AUTOSAR XML (schema 00045)
package /Cps
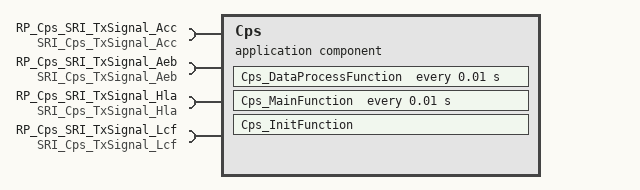
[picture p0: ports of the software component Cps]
  application sw component type Cps  # Communication Process of Sender
    4 x require port:
      RP_Cps_SRI_TxSignal_Acc: required-interface=SRI_Cps_TxSignal_Acc
      RP_Cps_SRI_TxSignal_Aeb: required-interface=SRI_Cps_TxSignal_Aeb
      RP_Cps_SRI_TxSignal_Hla: required-interface=SRI_Cps_TxSignal_Hla
      RP_Cps_SRI_TxSignal_Lcf: required-interface=SRI_Cps_TxSignal_Lcf
    behavior Cps_IB: handle-termination-and-restart=NO-SUPPORT
      init event InitEvent_Cps_InitFunction: start-on-event=Cps_InitFunction
      timing event TimingEvent_Cps_DataProcessFunction: start-on-event=Cps_DataProcessFunction, period=0.01
      timing event TimingEvent_Cps_MainFunction: start-on-event=Cps_MainFunction, period=0.01
      runnable Cps_DataProcessFunction
      runnable Cps_InitFunction
      runnable Cps_MainFunction
        data-receive-point-by-arguments:
          57 x access:
            drparg_Cps_SignalPhyData_ACC: accessed-variable=RP_Cps_SRI_TxSignal_Lcf.Cps_SignalPhyData_ACC_HostLaneLeftStatus
            drparg_Cps_SignalPhyData_ACC0: accessed-variable=RP_Cps_SRI_TxSignal_Lcf.Cps_SignalPhyData_ACC_HostLaneRightStatus
            drparg_Cps_SignalPhyData_ACC1: accessed-variable=RP_Cps_SRI_TxSignal_Lcf.Cps_SignalPhyData_ACC_LatAngReq
            drparg_Cps_SignalPhyData_ACC2: accessed-variable=RP_Cps_SRI_TxSignal_Lcf.Cps_SignalPhyData_ACC_LatAngReqActive
            drparg_Cps_SignalPhyData_FC_: accessed-variable=RP_Cps_SRI_TxSignal_Lcf.Cps_SignalPhyData_FC_HostLaneLeftStatus
            drparg_Cps_SignalPhyData_FC_0: accessed-variable=RP_Cps_SRI_TxSignal_Acc.Cps_SignalPhyData_FC_ACC_temp
            drparg_Cps_SignalPhyData_FC_1: accessed-variable=RP_Cps_SRI_TxSignal_Aeb.Cps_SignalPhyData_FC_AEBActive
            drparg_Cps_SignalPhyData_FC_10: accessed-variable=RP_Cps_SRI_TxSignal_Aeb.Cps_SignalPhyData_FC_AEBTargetmode
            drparg_Cps_SignalPhyData_FC_11: accessed-variable=RP_Cps_SRI_TxSignal_Aeb.Cps_SignalPhyData_FC_AEBTextInfo
            drparg_Cps_SignalPhyData_FC_12: accessed-variable=RP_Cps_SRI_TxSignal_Aeb.Cps_SignalPhyData_FC_AEBVehilceHoldReq
            drparg_Cps_SignalPhyData_FC_13: accessed-variable=RP_Cps_SRI_TxSignal_Aeb.Cps_SignalPhyData_FC_OBJ_AEB_ID
            drparg_Cps_SignalPhyData_FC_14: accessed-variable=RP_Cps_SRI_TxSignal_Aeb.Cps_SignalPhyData_FC_AEBStatus
            drparg_Cps_SignalPhyData_FC_15: accessed-variable=RP_Cps_SRI_TxSignal_Aeb.Cps_SignalPhyData_FC_AEBTargetAy
            drparg_Cps_SignalPhyData_FC_16: accessed-variable=RP_Cps_SRI_TxSignal_Aeb.Cps_SignalPhyData_FC_AEBTargetAx
            drparg_Cps_SignalPhyData_FC_17: accessed-variable=RP_Cps_SRI_TxSignal_Aeb.Cps_SignalPhyData_FC_AEBTargetProb
            drparg_Cps_SignalPhyData_FC_18: accessed-variable=RP_Cps_SRI_TxSignal_Aeb.Cps_SignalPhyData_FC_AEBTargetLatRelSpeed
            drparg_Cps_SignalPhyData_FC_19: accessed-variable=RP_Cps_SRI_TxSignal_Aeb.Cps_SignalPhyData_FC_FCWStatus
            drparg_Cps_SignalPhyData_FC_2: accessed-variable=RP_Cps_SRI_TxSignal_Aeb.Cps_SignalPhyData_FC_AEBCtrlType
            drparg_Cps_SignalPhyData_FC_20: accessed-variable=RP_Cps_SRI_TxSignal_Aeb.Cps_SignalPhyData_FC_PrefillActive
            drparg_Cps_SignalPhyData_FC_21: accessed-variable=RP_Cps_SRI_TxSignal_Aeb.Cps_SignalPhyData_FC_AWBlevel
            drparg_Cps_SignalPhyData_FC_22: accessed-variable=RP_Cps_SRI_TxSignal_Aeb.Cps_SignalPhyData_FC_AWBActive
            drparg_Cps_SignalPhyData_FC_23: accessed-variable=RP_Cps_SRI_TxSignal_Aeb.Cps_SignalPhyData_FC_FCWActive
            drparg_Cps_SignalPhyData_FC_24: accessed-variable=RP_Cps_SRI_TxSignal_Aeb.Cps_SignalPhyData_FC_ABAlevel
            drparg_Cps_SignalPhyData_FC_25: accessed-variable=RP_Cps_SRI_TxSignal_Aeb.Cps_SignalPhyData_FC_ABAActive
            drparg_Cps_SignalPhyData_FC_26: accessed-variable=RP_Cps_SRI_TxSignal_Aeb.Cps_SignalPhyData_FC_FCWPreWarning
            drparg_Cps_SignalPhyData_FC_27: accessed-variable=RP_Cps_SRI_TxSignal_Aeb.Cps_SignalPhyData_FC_FCWLatentWarning
            drparg_Cps_SignalPhyData_FC_28: accessed-variable=RP_Cps_SRI_TxSignal_Aeb.Cps_SignalPhyData_FC_FCWSettingStatus
            drparg_Cps_SignalPhyData_FC_29: accessed-variable=RP_Cps_SRI_TxSignal_Lcf.Cps_SignalPhyData_FC_LatAngReqActive
            drparg_Cps_SignalPhyData_FC_3: accessed-variable=RP_Cps_SRI_TxSignal_Aeb.Cps_SignalPhyData_FC_AEBEnable
            drparg_Cps_SignalPhyData_FC_30: accessed-variable=RP_Cps_SRI_TxSignal_Lcf.Cps_SignalPhyData_FC_LDWStatus
            drparg_Cps_SignalPhyData_FC_31: accessed-variable=RP_Cps_SRI_TxSignal_Lcf.Cps_SignalPhyData_FC_LDWVibrationWarningReq
            drparg_Cps_SignalPhyData_FC_32: accessed-variable=RP_Cps_SRI_TxSignal_Lcf.Cps_SignalPhyData_FC_LKAStatus
            drparg_Cps_SignalPhyData_FC_33: accessed-variable=RP_Cps_SRI_TxSignal_Lcf.Cps_SignalPhyData_FC_LKATakeoverReq
            drparg_Cps_SignalPhyData_FC_34: accessed-variable=RP_Cps_SRI_TxSignal_Lcf.Cps_SignalPhyData_FC_LASModeSelectionStatus
            drparg_Cps_SignalPhyData_FC_35: accessed-variable=RP_Cps_SRI_TxSignal_Lcf.Cps_SignalPhyData_FC_LASWarningModeSelectionSts
            drparg_Cps_SignalPhyData_FC_36: accessed-variable=RP_Cps_SRI_TxSignal_Lcf.Cps_SignalPhyData_FC_LDWShakeLevStatus
            drparg_Cps_SignalPhyData_FC_37: accessed-variable=RP_Cps_SRI_TxSignal_Lcf.Cps_SignalPhyData_FC_ELKMode
            drparg_Cps_SignalPhyData_FC_38: accessed-variable=RP_Cps_SRI_TxSignal_Lcf.Cps_SignalPhyData_FC_ELKInterventionMode
            drparg_Cps_SignalPhyData_FC_39: accessed-variable=RP_Cps_SRI_TxSignal_Lcf.Cps_SignalPhyData_FC_ELKEnableStatus
            drparg_Cps_SignalPhyData_FC_4: accessed-variable=RP_Cps_SRI_TxSignal_Aeb.Cps_SignalPhyData_FC_AEBTargetDeceleration
            drparg_Cps_SignalPhyData_FC_40: accessed-variable=RP_Cps_SRI_TxSignal_Lcf.Cps_SignalPhyData_FC_LatAngReq
            drparg_Cps_SignalPhyData_FC_41: accessed-variable=RP_Cps_SRI_TxSignal_Lcf.Cps_SignalPhyData_FC_MotorTorqueMaxLimitRequest
            drparg_Cps_SignalPhyData_FC_42: accessed-variable=RP_Cps_SRI_TxSignal_Lcf.Cps_SignalPhyData_FC_MotorTorqueMinLimitRequest
            drparg_Cps_SignalPhyData_FC_43: accessed-variable=RP_Cps_SRI_TxSignal_Lcf.Cps_SignalPhyData_FC_Voiceinfo
            drparg_Cps_SignalPhyData_FC_44: accessed-variable=RP_Cps_SRI_TxSignal_Hla.Cps_SignalPhyData_FC_HMALightDistribution
            drparg_Cps_SignalPhyData_FC_45: accessed-variable=RP_Cps_SRI_TxSignal_Hla.Cps_SignalPhyData_FC_HMAEnableStatus
            drparg_Cps_SignalPhyData_FC_46: accessed-variable=RP_Cps_SRI_TxSignal_Hla.Cps_SignalPhyData_FC_HMAStatus
            drparg_Cps_SignalPhyData_FC_47: accessed-variable=RP_Cps_SRI_TxSignal_Lcf.Cps_SignalPhyData_FC_HostLaneRightStatus
            drparg_Cps_SignalPhyData_FC_48: accessed-variable=RP_Cps_SRI_TxSignal_Aeb.Cps_SignalPhyData_FC_LLaneDistanceFus
            drparg_Cps_SignalPhyData_FC_49: accessed-variable=RP_Cps_SRI_TxSignal_Aeb.Cps_SignalPhyData_FC_RLaneDistanceFus
            drparg_Cps_SignalPhyData_FC_5: accessed-variable=RP_Cps_SRI_TxSignal_Aeb.Cps_SignalPhyData_FC_AEBTargetDetection
            drparg_Cps_SignalPhyData_FC_50: accessed-variable=RP_Cps_SRI_TxSignal_Aeb.Cps_SignalPhyData_FC_LLaneMarkerType
            drparg_Cps_SignalPhyData_FC_51: accessed-variable=RP_Cps_SRI_TxSignal_Aeb.Cps_SignalPhyData_FC_RLaneMarkerType
            drparg_Cps_SignalPhyData_FC_6: accessed-variable=RP_Cps_SRI_TxSignal_Aeb.Cps_SignalPhyData_FC_AEBTargetLatRange
            drparg_Cps_SignalPhyData_FC_7: accessed-variable=RP_Cps_SRI_TxSignal_Aeb.Cps_SignalPhyData_FC_AEBTargetLngRange
            drparg_Cps_SignalPhyData_FC_8: accessed-variable=RP_Cps_SRI_TxSignal_Aeb.Cps_SignalPhyData_FC_AEBTargetRelSpeed
            drparg_Cps_SignalPhyData_FC_9: accessed-variable=RP_Cps_SRI_TxSignal_Aeb.Cps_SignalPhyData_FC_AEBTargetType
  swc implementation CpsImpl: programming-language=C, sw-version=0.0.1, vendor-id=0, behavior=Cps_IB
    code-descriptors:
      code CodeGen: artifact-descriptors=[{short-label=SWSRC, category=SWSRC}, {short-label=SWHDR, category=SWHDR}]
    resource consumption Resource
      memory section CODE: sw-addrmethod=CODE
      memory section VAR_UNSPECIFIED: sw-addrmethod=VAR
